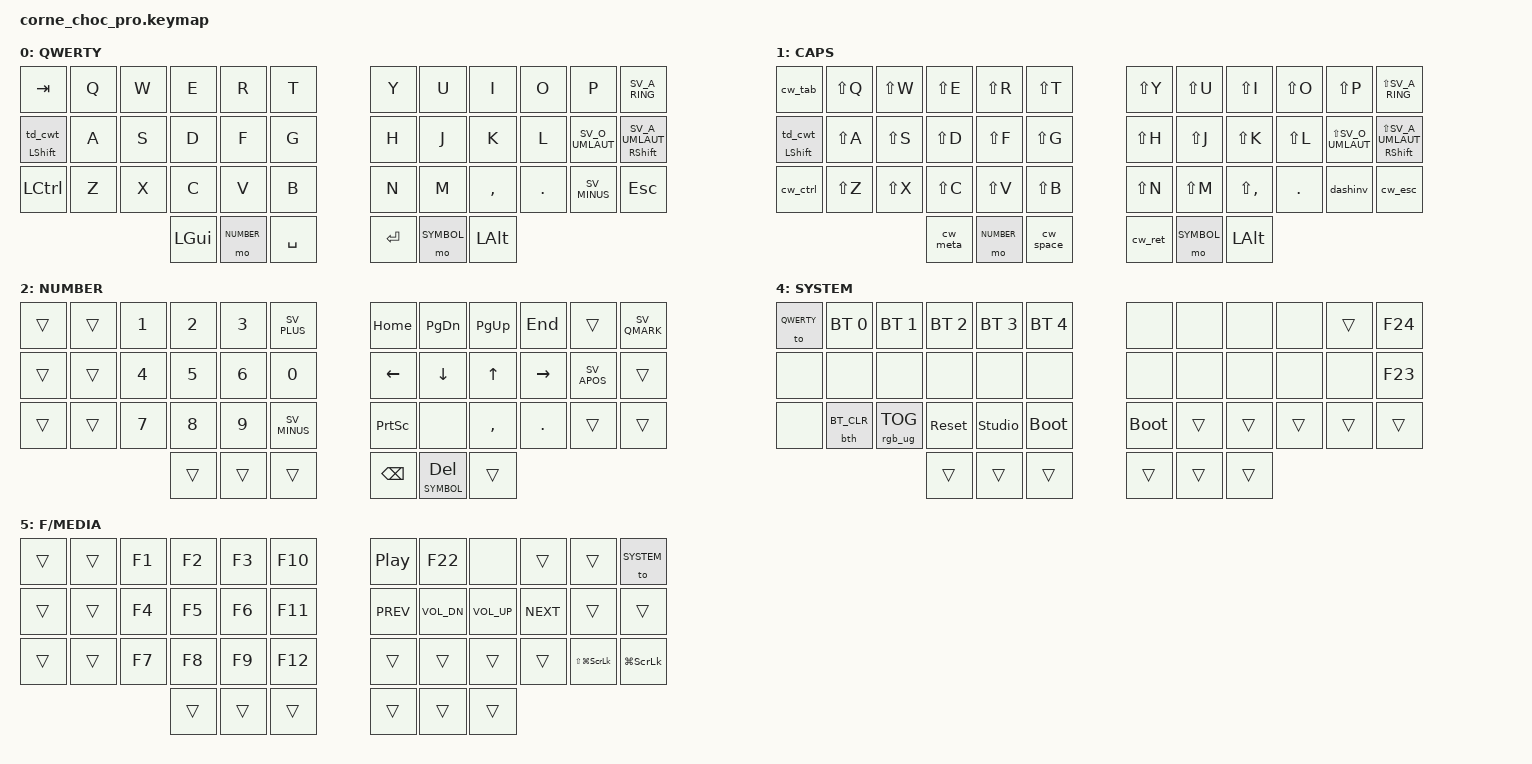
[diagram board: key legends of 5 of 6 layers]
/*
 * Copyright (c) 2020 The ZMK Contributors
 *
 * SPDX-License-Identifier: MIT
 */

#include <behaviors.dtsi>
#include <dt-bindings/zmk/bt.h>
#include <dt-bindings/zmk/keys.h>
#include <dt-bindings/zmk/rgb.h>
#include <locale/keys_sv.h>

#define QWERTY      0
#define CAPS_LAYER  1
#define NUMBER      2
#define SYMBOL      3
#define SYSTEM      4
#define F_MEDIA     5

/ {
  chosen { zmk,physical-layout = &default_layout; };
};

&caps_word {
    continue-list = <UNDERSCORE MINUS SV_MINUS>;
};

&lt {
    quick-tap-ms = <200>;
    tapping-term-ms = <200>;
};

/ {
    conditional_layers {
        compatible = "zmk,conditional-layers";
        tri_layer {
            if-layers = <NUMBER SYMBOL>;
            then-layer = <F_MEDIA>;
        };
    };
};

/ {
    macros {
        macro_e_acute: macro_e_acute {
            compatible = "zmk,behavior-macro";
            #binding-cells = <0>;
            bindings = <&kp SV_ACUTE &kp E>;
        };
    };

    combos {
        compatible = "zmk,combos";
        combo_e_acute {
            timeout-ms = <50>;
            key-positions = <3 4>; /* E + R */
            bindings = <&macro_e_acute>;
        };
    };
};

/ {
  behaviors {
    ncw: new_caps_word {
      label = "caps_word_caps_word";
      compatible = "zmk,behavior-macro";
      #binding-cells = <0>;
      bindings = <&macro_tap &tog CAPS_LAYER>;
    };

    cw_tab: caps_word_tab {
      label = "caps_word_tab";
      compatible = "zmk,behavior-macro";
      #binding-cells = <0>;
      bindings = <&macro_tap &kp TAB &tog CAPS_LAYER>;
    };

    cw_ctrl: caps_word_ctrl {
      label = "caps_word_ctrl";
      compatible = "zmk,behavior-macro";
      #binding-cells = <0>;
      bindings =
        <&macro_tap &tog CAPS_LAYER>,
        <&macro_press &kp LCTRL>,
        <&macro_pause_for_release>,
        <&macro_release &kp LCTRL>;
    };

    cw_meta: caps_word_meta {
      label = "caps_word_meta";
      compatible = "zmk,behavior-macro";
      #binding-cells = <0>;
      bindings =
        <&macro_tap &tog CAPS_LAYER>,
        <&macro_press &kp LGUI>,
        <&macro_pause_for_release>,
        <&macro_release &kp LGUI>;
    };

    cw_space: caps_word_space {
      label = "caps_word_space";
      compatible = "zmk,behavior-macro";
      #binding-cells = <0>;
      bindings = <&macro_tap &kp SPACE &tog CAPS_LAYER>;
    };

    cw_ret: caps_word_return {
      label = "caps_word_return";
      compatible = "zmk,behavior-macro";
      #binding-cells = <0>;
      bindings = <&macro_tap &kp RET &tog CAPS_LAYER>;
    };

    cw_esc: caps_word_esc {
      label = "caps_word_esc";
      compatible = "zmk,behavior-macro";
      #binding-cells = <0>;
      bindings = <&macro_tap &kp ESC &tog CAPS_LAYER>;
    };

    cwt: caps_word_tap {
      compatible = "zmk,behavior-hold-tap";
      #binding-cells = <2>;
      flavor = "hold-preferred";
      tapping-term-ms = <200>;
      bindings = <&kp>, <&td_cwt>;
      display-name = "Caps-Word-Tap";
    };

    td_cwt: tap_dance_caps_word_tap {
      compatible = "zmk,behavior-tap-dance";
      #binding-cells = <0>;
      tapping-term-ms = <400>;
      bindings = <&kp LSHFT>, <&ncw>, <&kp CAPS>;
    };

    ht: hold_tap {
      compatible = "zmk,behavior-hold-tap";
      #binding-cells = <2>;
      flavor = "tap-preferred";
      quick-tap-ms = <200>;
      tapping-term-ms = <200>;
      require-prior-idle-ms = <125>;
      bindings = <&kp>, <&kp>;
      display-name = "Hold-tap";
    };

    acinv: acute_inverted {
      compatible = "zmk,behavior-mod-morph";
      #binding-cells = <0>;
      bindings = <&kp LS(SV_ACUTE)>, <&kp SV_ACUTE>;
      mods = <(MOD_LSFT|MOD_RSFT)>;
    };

    codeblock: codeblock {
      compatible = "zmk,behavior-macro";
      #binding-cells = <0>;
      bindings = <&macro_tap &kp LS(SV_ACUTE) &kp LS(SV_ACUTE) &kp LS(SV_ACUTE) &kp LS(SV_ACUTE) &kp LS(SV_ACUTE) &kp LS(SV_ACUTE) &kp RET &kp RET &kp LS(SV_ACUTE) &kp LS(SV_ACUTE) &kp LS(SV_ACUTE) &kp LS(SV_ACUTE) &kp LS(SV_ACUTE) &kp LS(SV_ACUTE) &kp UP>;
    };

    acblock: acblock {
      compatible = "zmk,behavior-hold-tap";
      #binding-cells = <2>;
      flavor = "tap-preferred";
      quick-tap-ms = <1000>;
      tapping-term-ms = <1000>;
      require-prior-idle-ms = <125>;
      bindings = <&codeblock>, <&acinv>;
    };

    dotinv: dot_inverted {
      compatible = "zmk,behavior-mod-morph";
      #binding-cells = <0>;
      bindings = <&kp LS(DOT)>, <&kp DOT>;
      mods = <(MOD_LSFT|MOD_RSFT)>;
    };

    dashinv: dash_inverted {
      compatible = "zmk,behavior-mod-morph";
      #binding-cells = <0>;
      bindings = <&kp LS(SV_MINUS)>, <&kp SV_MINUS>;
      mods = <(MOD_LSFT|MOD_RSFT)>;
    };

    bth: behavior_bth {
      compatible = "zmk,behavior-hold-tap";
      label = "BT_HOLD";
      #binding-cells = <2>;
      tapping-term-ms = <5000>;
      quick-tap-ms = <0>;
      flavor = "tap-preferred";
      bindings = <&bt>, <&none>;
    };
  };

  keymap {
    compatible = "zmk,keymap";

    default_layer {
      display-name = "QWERTY";

      bindings = <
          &kp TAB        &kp Q   &kp W   &kp E      &kp R        &kp T           &kp Y     &kp U        &kp I       &kp O     &kp P             &kp SV_A_RING
          &cwt LSHFT 0   &kp A   &kp S   &kp D      &kp F        &kp G           &kp H     &kp J        &kp K       &kp L     &kp SV_O_UMLAUT   &ht RSHFT SV_A_UMLAUT
          &kp LCTRL      &kp Z   &kp X   &kp C      &kp V        &kp B           &kp N     &kp M        &kp COMMA   &kp DOT   &kp SV_MINUS      &kp ESC
                                         &kp LGUI   &mo NUMBER   &kp SPACE       &kp RET   &mo SYMBOL   &kp LALT
      >;
    };

    caps_layer {
      display-name = "CAPS";

      bindings = <
          &cw_tab        &kp LS(Q)   &kp LS(W)   &kp LS(E)   &kp LS(R)    &kp LS(T)       &kp LS(Y)   &kp LS(U)    &kp LS(I)       &kp LS(O)   &kp LS(P)             &kp LS(SV_A_RING)
          &cwt LSHFT 0   &kp LS(A)   &kp LS(S)   &kp LS(D)   &kp LS(F)    &kp LS(G)       &kp LS(H)   &kp LS(J)    &kp LS(K)       &kp LS(L)   &kp LS(SV_O_UMLAUT)   &ht RSHFT LS(SV_A_UMLAUT)
          &cw_ctrl       &kp LS(Z)   &kp LS(X)   &kp LS(C)   &kp LS(V)    &kp LS(B)       &kp LS(N)   &kp LS(M)    &kp LS(COMMA)   &kp DOT     &dashinv              &cw_esc
                                                 &cw_meta    &mo NUMBER   &cw_space       &cw_ret     &mo SYMBOL   &kp LALT
      >;
    };

    lower_layer {
      display-name = "NUMBER";

      bindings = <
          &trans   &trans   &kp N1   &kp N2   &kp N3   &kp SV_PLUS        &kp HOME    &kp PG_DN        &kp PG_UP   &kp END     &trans        &kp SV_QMARK
          &trans   &trans   &kp N4   &kp N5   &kp N6   &kp N0             &kp LEFT    &kp DOWN         &kp UP      &kp RIGHT   &kp SV_APOS   &trans
          &trans   &trans   &kp N7   &kp N8   &kp N9   &kp SV_MINUS       &kp PSCRN   &none            &kp COMMA   &kp DOT     &trans        &trans
                                     &trans   &trans   &trans             &kp BSPC    &lt SYMBOL DEL   &trans
      >;
    };

    symbol_layer {
      display-name = "SYMBOL";

      bindings = <
          &trans   &none   &kp SV_DQT    &kp SV_LT      &kp SV_GT      &kp SV_PIPE        &kp SV_CARET   &kp SV_LBRC      &kp SV_RBRC   &kp SV_DLLR    &kp SV_APOS    &acblock &codeblock &acinv
          &trans   &none   &kp SV_EXCL   &kp SV_LBKT    &kp SV_RBKT    &kp SV_AMPS        &kp SV_FSLH    &kp SV_LPAR      &kp SV_RPAR   &kp SV_QMARK   &kp SV_BSLH    &kp SV_APOS
          &trans   &none   &kp SV_HASH   &kp SV_QMARK   &kp SV_EQUAL   &kp SV_PRCNT       &kp SV_TILDE   &kp SV_AT_SIGN   &kp COMMA     &dotinv        &kp SV_MINUS   &trans
                                         &trans         &mo NUMBER     &trans             &trans         &trans           &trans
      >;
    };

    system_layer {
      display-name = "SYSTEM";
      bindings = <
          &to QWERTY   &bt BT_SEL 0   &bt BT_SEL 1      &bt BT_SEL 2   &bt BT_SEL 3     &bt BT_SEL 4       &none         &none    &none    &none    &trans   &kp F24
          &none        &none          &none             &none          &none            &none              &none         &none    &none    &none    &none    &kp F23
          &none        &bth BT_CLR    &rgb_ug RGB_TOG   &sys_reset     &studio_unlock   &bootloader        &bootloader   &trans   &trans   &trans   &trans   &trans
                                                        &trans         &trans           &trans             &trans        &trans   &trans
      >;
    };

    f_media_layer {
      display-name = "F/MEDIA";
      bindings = <
          &trans   &trans   &kp F1   &kp F2   &kp F3   &kp F10       &kp C_PLAY_PAUSE   &kp F22        &none          &trans       &trans             &to SYSTEM
          &trans   &trans   &kp F4   &kp F5   &kp F6   &kp F11       &kp C_PREV         &kp C_VOL_DN   &kp C_VOL_UP   &kp C_NEXT   &trans             &trans
          &trans   &trans   &kp F7   &kp F8   &kp F9   &kp F12       &trans             &trans         &trans         &trans       &kp LS(LG(SLCK))   &kp LG(SLCK)
                                     &trans   &trans   &trans        &trans             &trans         &trans
      >;
    };
  };
};
